# STM32N655 register map
File version: 1.0
CPU: CM55 r0p1, little endian, no MPU, FPU, vendor SysTick, 8 interrupt priority bits
Registers are 32-bit, read-write, reset 0x0 unless marked. A register's access mark holds for its fields unless they carry their own. Offsets are from the block's base; [hi:lo] are bit positions; {n}, {i} and the like mark numbered series.

## EXTI — Extended interrupts and event controller
Base 0x46025000
Same registers: EXTI_S 0x56025000
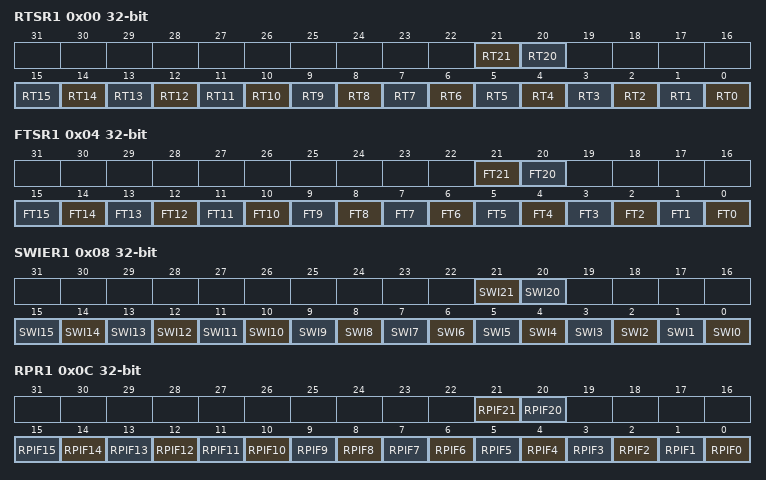
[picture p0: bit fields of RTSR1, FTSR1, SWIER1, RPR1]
0x00 RTSR1 — EXTI rising trigger selection register
  [21] RT21 — Rising trigger event configuration bit of configurable event input x
  [20] RT20 — Rising trigger event configuration bit of configurable event input x
  [n] RT{n} (n=0..15) — Rising trigger event configuration bit of configurable event input x
0x04 FTSR1 — EXTI falling trigger selection register
  [21] FT21 — Falling trigger event configuration bit of configurable event input x
  [20] FT20 — Falling trigger event configuration bit of configurable event input x
  [n] FT{n} (n=0..15) — Falling trigger event configuration bit of configurable event input x
0x08 SWIER1 — EXTI software interrupt event register
  [21] SWI21 — Software interrupt on event x
  [20] SWI20 — Software interrupt on event x
  [n] SWI{n} (n=0..15) — Software interrupt on event x
0x0C RPR1 — EXTI rising edge pending register
  [21] RPIF21 — Configurable event input x rising edge pending bit
  [20] RPIF20 — Configurable event input x rising edge pending bit
  [n] RPIF{n} (n=0..15) — Configurable event input x rising edge pending bit
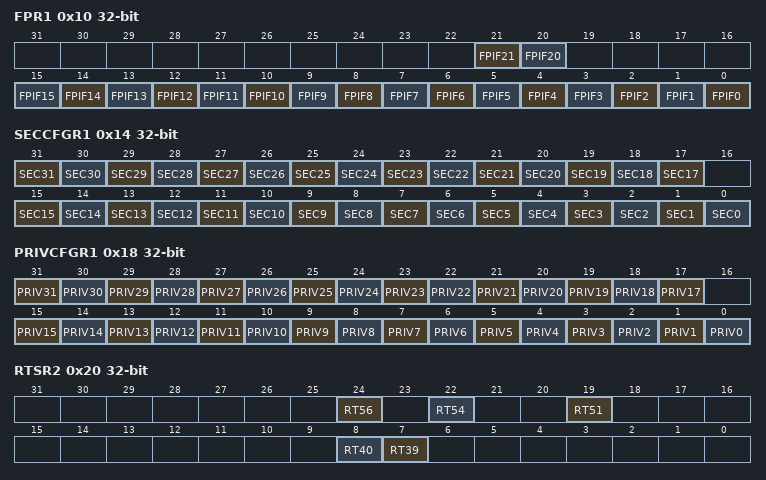
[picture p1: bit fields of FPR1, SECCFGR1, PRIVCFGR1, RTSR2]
0x10 FPR1 — EXTI falling edge pending register
  [21] FPIF21 — configurable event input x falling edge pending bit
  [20] FPIF20 — configurable event input x falling edge pending bit
  [n] FPIF{n} (n=0..15) — Configurable event input x rising edge pending bit
0x14 SECCFGR1 — EXTI security configuration register
  [n] SEC{n} (n=17..31) — Security enable on event input x
  [n] SEC{n} (n=0..15) — Security enable on event input x
0x18 PRIVCFGR1 — EXTI privilege configuration register
  [n] PRIV{n} (n=17..31) — Privilege enable on event input x
  [n] PRIV{n} (n=0..15) — Privilege enable on event input x
0x20 RTSR2 — EXTI rising trigger selection register
  [24] RT56 — Rising trigger event configuration bit of configurable event input 56
  [22] RT54 — Rising trigger event configuration bit of configurable event input 54
  [19] RT51 — Rising trigger event configuration bit of configurable event input 51
  [8] RT40 — Rising trigger event configuration bit of configurable event input x
  [7] RT39 — Rising trigger event configuration bit of configurable event input x
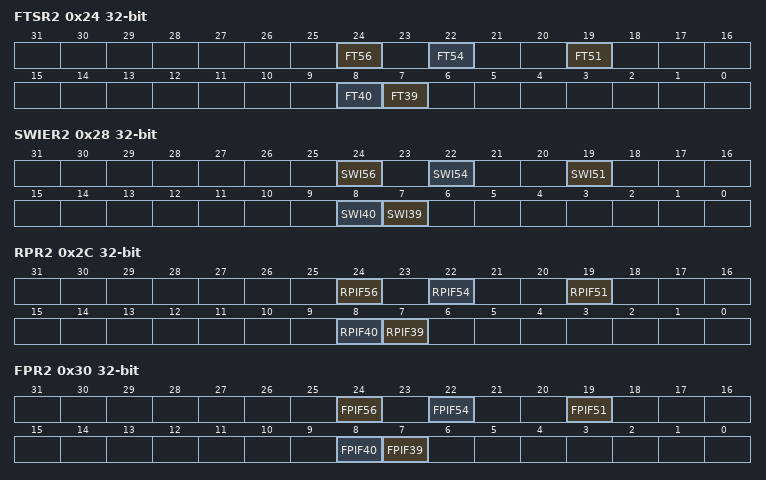
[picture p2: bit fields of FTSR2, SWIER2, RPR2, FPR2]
0x24 FTSR2 — EXTI falling trigger selection register
  [24] FT56 — Falling trigger event configuration bit of configurable event input 56
  [22] FT54 — Falling trigger event configuration bit of configurable event input 54
  [19] FT51 — Falling trigger event configuration bit of configurable event input 51
  [8] FT40 — Falling trigger event configuration bit of configurable event input x
  [7] FT39 — Falling trigger event configuration bit of configurable event input x
0x28 SWIER2 — EXTI software interrupt event register
  [24] SWI56 — Software interrupt on event 56
  [22] SWI54 — Software interrupt on event 54
  [19] SWI51 — Software interrupt on event 51
  [8] SWI40 — Software interrupt on event x
  [7] SWI39 — Software interrupt on event x
0x2C RPR2 — EXTI rising edge pending register
  [24] RPIF56 — Configurable event input 56 rising edge pending bit
  [22] RPIF54 — Configurable event input 54 rising edge pending bit
  [19] RPIF51 — Configurable event input 51 rising edge pending bit
  [8] RPIF40 — Configurable event input x rising edge pending bit
  [7] RPIF39 — Configurable event input x rising edge pending bit
0x30 FPR2 — EXTI falling edge pending register
  [24] FPIF56 — Configurable event input 56 falling edge pending bit
  [22] FPIF54 — Configurable event input 54 falling edge pending bit
  [19] FPIF51 — Configurable event input 51 falling edge pending bit
  [8] FPIF40 — Configurable event input x falling edge pending bit
  [7] FPIF39 — Configurable event input x falling edge pending bit
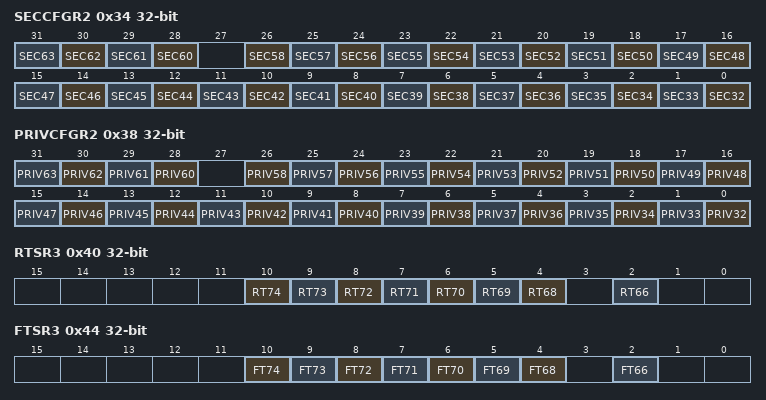
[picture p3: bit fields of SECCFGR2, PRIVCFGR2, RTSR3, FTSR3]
0x34 SECCFGR2 — EXTI security enable register
  [n-32] SEC{n} (n=60..63) — Security enable on event input x
  [n-32] SEC{n} (n=32..58) — Security enable on event input x
0x38 PRIVCFGR2 — EXTI privilege enable register
  [n-32] PRIV{n} (n=60..63) — Privilege enable on event input x
  [n-32] PRIV{n} (n=32..58) — Privilege enable on event input x
0x40 RTSR3 — EXTI rising trigger selection register
  [n-64] RT{n} (n=68..74) — Rising trigger event configuration bit of configurable event input x
  [2] RT66 — Rising trigger event configuration bit of configurable event input 66
0x44 FTSR3 — EXTI falling trigger selection register
  [n-64] FT{n} (n=68..74) — Falling trigger event configuration bit of configurable event input x
  [2] FT66 — Falling trigger event configuration bit of configurable event input 66
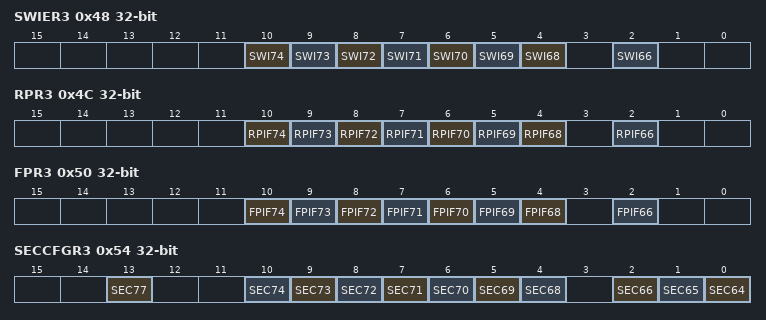
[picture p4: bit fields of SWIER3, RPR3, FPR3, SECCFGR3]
0x48 SWIER3 — EXTI software interrupt event register
  [n-64] SWI{n} (n=68..74) — Software interrupt on event x
  [2] SWI66 — Software interrupt on event 66
0x4C RPR3 — EXTI rising edge pending register
  [n-64] RPIF{n} (n=68..74) — configurable event input x rising edge pending bit
  [2] RPIF66 — configurable event input 66rising edge pending bit
0x50 FPR3 — EXTI falling edge pending register
  [n-64] FPIF{n} (n=68..74) — configurable event input x falling edge pending bit
  [2] FPIF66 — configurable event input 66 falling edge pending bit
0x54 SECCFGR3 — EXTI security enable register
  [13] SEC77 — Security enable on event input 77
  [n-64] SEC{n} (n=68..74) — Security enable on event input x
  [2] SEC66 — Security enable on event input x
  [1] SEC65 — Security enable on event input x
  [0] SEC64 — Security enable on event input x
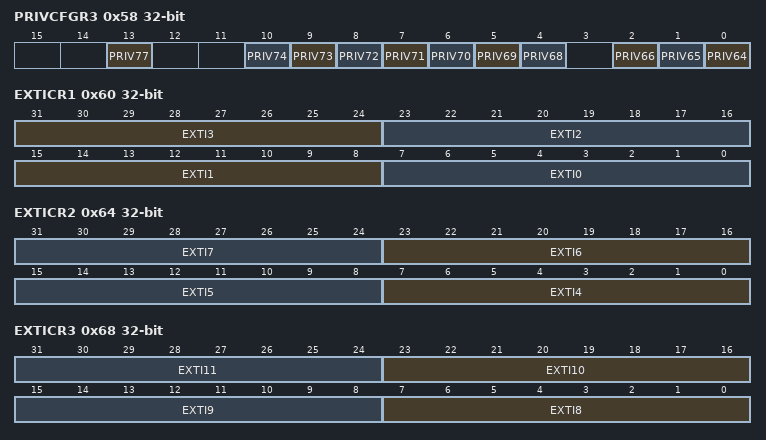
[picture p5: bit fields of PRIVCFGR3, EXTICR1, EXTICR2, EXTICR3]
0x58 PRIVCFGR3 — EXTI privilege enable register
  [13] PRIV77 — Privilege enable on event input 77
  [n-64] PRIV{n} (n=68..74) — Privilege enable on event input x
  [2] PRIV66 — Privilege enable on event input x
  [1] PRIV65 — Privilege enable on event input x
  [0] PRIV64 — Privilege enable on event input x
0x60 EXTICR1 — EXTI external interrupt selection register 1
  [31:24] EXTI3 — EXTI3 GPIO port selection
  [23:16] EXTI2 — EXTI2 GPIO port selection
  [15:8] EXTI1 — EXTI1 GPIO port selection
  [7:0] EXTI0 — EXTI0 GPIO port selection.
0x64 EXTICR2 — EXTI external interrupt selection register 2
  [8n-25:8n-32] EXTI{n} (n=4..7) — EXTI{n} GPIO port selection.
0x68 EXTICR3 — EXTI external interrupt selection register 3
  [8n-57:8n-64] EXTI{n} (n=8..11) — EXTI{n} GPIO port selection.
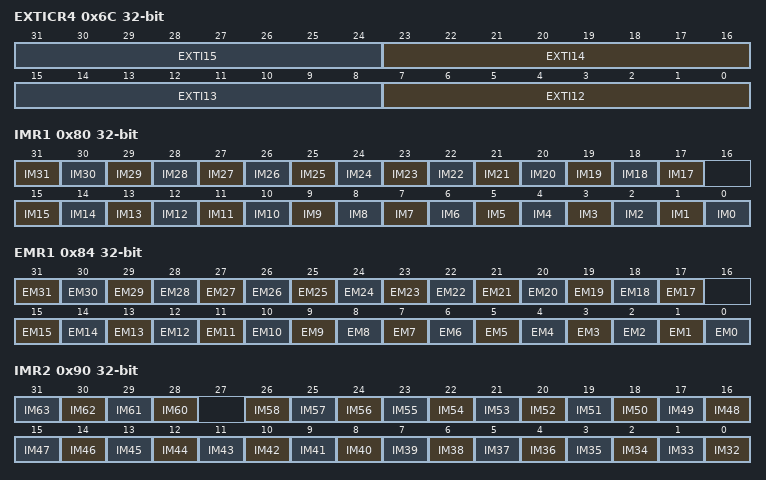
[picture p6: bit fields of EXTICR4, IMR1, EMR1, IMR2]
0x6C EXTICR4 — EXTI external interrupt selection register 4
  [8n-89:8n-96] EXTI{n} (n=12..15) — EXTI{n} GPIO port selection.
0x70 LOCKR — EXTI lock register
  [0] GLOCK — Global security privilege EXTI_SECCFGRx/PRIVCFGRx
0x80 IMR1 — EXTI CPU wake-up with interrupt mask register 1
  [n] IM{n} (n=17..31) — CPU wake-up with interrupt mask on event input x
  [n] IM{n} (n=0..15) — CPU wake-up with interrupt mask on event input x
0x84 EMR1 — EXTI CPU wake-up with event mask register 1
  [n] EM{n} (n=17..31) — CPU wake-up with event on event input x
  [n] EM{n} (n=0..15) — CPU wake-up with interrupt mask on event input x
0x90 IMR2 — EXTI CPU wake-up with interrupt mask register 2
  [n-32] IM{n} (n=60..63) — CPU wake-up with interrupt mask on event input x
  [n-32] IM{n} (n=32..58) — CPU wake-up with interrupt mask on event input x
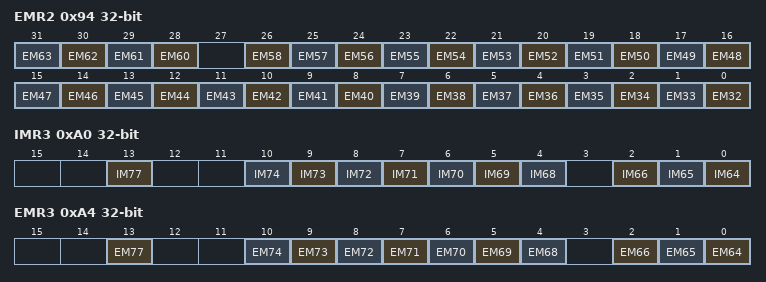
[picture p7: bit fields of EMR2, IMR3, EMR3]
0x94 EMR2 — EXTI CPU wake-up with event mask register 2
  [n-32] EM{n} (n=60..63) — CPU wake-up with event on event input x
  [n-32] EM{n} (n=32..58) — CPU wake-up with interrupt mask on event input x
0xA0 IMR3 — EXTI CPU wake-up with interrupt mask register 3
  [13] IM77 — CPU wake-up with interrupt mask on event input 77
  [n-64] IM{n} (n=68..74) — CPU wake-up with interrupt mask on event input x
  [2] IM66 — CPU wake-up with interrupt mask on event input x
  [1] IM65 — CPU wake-up with interrupt mask on event input x
  [0] IM64 — CPU wake-up with interrupt mask on event input x
0xA4 EMR3 — EXTI CPU wake-up with event mask register 3
  [13] EM77 — CPU wake-up with event on event input 77
  [n-64] EM{n} (n=68..74) — CPU wake-up with interrupt mask on event input x
  [2] EM66 — CPU wake-up with interrupt mask on event input x
  [1] EM65 — CPU wake-up with interrupt mask on event input x
  [0] EM64 — CPU wake-up with interrupt mask on event input x
